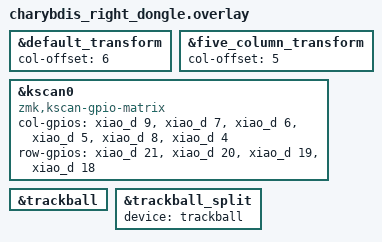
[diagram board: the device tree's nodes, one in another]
#include "../charybdis_common/charybdis.dtsi"
#include "../charybdis_trackball/charybdis_pmw3610.dtsi"
#include "../../config/trackball/charybdis_pointer.dtsi"


// The matrix transform is 6 columns over because the left half is 6 columns wide.
&default_transform {
	col-offset = <6>;
};

&five_column_transform {
	col-offset = <5>;
};

&kscan0 {
	compatible = "zmk,kscan-gpio-matrix";
    
	col-gpios
		= <&xiao_d 9 GPIO_ACTIVE_HIGH>
		, <&xiao_d 7 GPIO_ACTIVE_HIGH>
		, <&xiao_d 6 GPIO_ACTIVE_HIGH>
		, <&xiao_d 5 GPIO_ACTIVE_HIGH>
		, <&xiao_d 8 GPIO_ACTIVE_HIGH>
		, <&xiao_d 4 GPIO_ACTIVE_HIGH>
		;

	row-gpios
		= <&xiao_d 21 (GPIO_ACTIVE_HIGH | GPIO_PULL_DOWN)>
		, <&xiao_d 20 (GPIO_ACTIVE_HIGH | GPIO_PULL_DOWN)>
		, <&xiao_d 19 (GPIO_ACTIVE_HIGH | GPIO_PULL_DOWN)>
		, <&xiao_d 18 (GPIO_ACTIVE_HIGH | GPIO_PULL_DOWN)>
		;
};

&trackball {
  status = "okay";
};

/* Enable the trackball listener on the peripheral with the sensor */
&trackball_split {
  device = <&trackball>;
  status = "okay";
};
